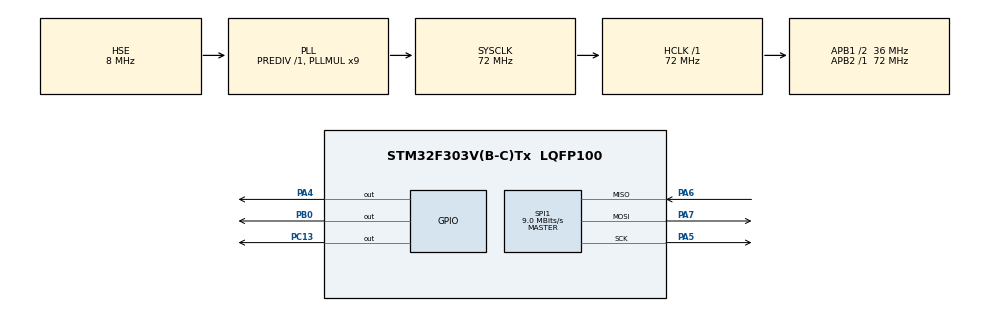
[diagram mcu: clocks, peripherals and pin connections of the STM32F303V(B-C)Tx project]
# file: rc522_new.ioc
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Mcu.Family=STM32F3
Mcu.Name=STM32F303V(B-C)Tx
Mcu.Package=LQFP100
NVIC.PriorityGroup=NVIC_PRIORITYGROUP_4
PA13.Mode=Serial_Wire
PA13.Signal=SYS_JTMS-SWDIO
PA14.Mode=Serial_Wire
PA14.Signal=SYS_JTCK-SWCLK
PA4.Signal=GPIO_Output
PA5.Mode=Full_Duplex_Master
PA5.Signal=SPI1_SCK
PA6.Mode=Full_Duplex_Master
PA6.Signal=SPI1_MISO
PA7.Mode=Full_Duplex_Master
PA7.Signal=SPI1_MOSI
PB0.Signal=GPIO_Output
PC13.Signal=GPIO_Output
PF0-OSC_IN.Mode=HSE-External-Oscillator
PF0-OSC_IN.Signal=RCC_OSC_IN
PF1-OSC_OUT.Mode=HSE-External-Oscillator
PF1-OSC_OUT.Signal=RCC_OSC_OUT
ProjectManager.HeapSize=0x200
ProjectManager.StackSize=0x400
ProjectManager.TargetToolchain=STM32CubeIDE
RCC.AHBFreq_Value=72000000
RCC.APB1CLKDivider=RCC_HCLK_DIV2
RCC.APB1Freq_Value=36000000
RCC.APB1TimFreq_Value=72000000
RCC.APB2Freq_Value=72000000
RCC.APB2TimFreq_Value=72000000
RCC.CortexFreq_Value=72000000
RCC.HCLKFreq_Value=72000000
RCC.HSE_VALUE=8000000
RCC.HSI_VALUE=8000000
RCC.LSE_VALUE=32768
RCC.PLLMUL=RCC_PLL_MUL9
RCC.PLLSourceVirtual=RCC_PLLSOURCE_HSE
RCC.SYSCLKFreq_VALUE=72000000
RCC.SYSCLKSourceVirtual=RCC_SYSCLKSOURCE_PLLCLK
RCC.USBFreq_Value=72000000
SPI1.BaudRatePrescaler=SPI_BAUDRATEPRESCALER_8
SPI1.CalculateBaudRate=9.0 MBits/s
SPI1.Direction=SPI_DIRECTION_2LINES
SPI1.Mode=SPI_MODE_MASTER
SPI1.VirtualType=VM_MASTER
board=custom

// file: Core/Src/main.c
/* USER CODE BEGIN Header */
/**
  ******************************************************************************
  * @file           : main.c
  * @brief          : Main program body
  ******************************************************************************
  * @attention
  *
  * Copyright (c) 2024 STMicroelectronics.
  * All rights reserved.
  *
  * This software is licensed under terms that can be found in the LICENSE file
  * in the root directory of this software component.
  * If no LICENSE file comes with this software, it is provided AS-IS.
  *
  ******************************************************************************
  */
/* USER CODE END Header */
#include "main.h"

/* USER CODE BEGIN Includes */
#include "rc522.h"
#include <string.h>
#include "stm32f3xx_hal.h"
/* USER CODE END Includes */

/* USER CODE BEGIN PD */
#define TIMEOUT_MS 2000  // Timeout period in milliseconds
/* USER CODE END PD */

SPI_HandleTypeDef hspi1;

/* USER CODE BEGIN PV */
uint8_t stored_uid[5] = {172, 74, 39, 204, 13};  // Pre-stored UID
uint8_t current_uid[5];  // Buffer to store the UID read from the RFID card
uint8_t sNum[5];  // Buffer to store the UID for live expression observation
uint8_t status;   // Status of MFRC522 functions
char uid_match;   // Character to indicate if UID matches
uint32_t last_detected_time = 0;  // Time when the last card was detected
/* USER CODE END PV */

void SystemClock_Config(void);
static void MX_GPIO_Init(void);
static void MX_SPI1_Init(void);

int main(void)
{

  /* MCU Configuration--------------------------------------------------------*/

  /* Reset of all peripherals, Initializes the Flash interface and the Systick. */
	HAL_Init();

  /* Configure the system clock */
  SystemClock_Config();

  /* Initialize all configured peripherals */
  MX_GPIO_Init();
  MX_SPI1_Init();
  MFRC522_Init();  // Initialize the MFRC522 module

  /* Infinite loop */
  /* USER CODE BEGIN WHILE */
  while (1)
  {
    // Check for a card presence
    status = MFRC522_Request(PICC_REQIDL, current_uid);
    if (status == MI_OK) {
      // If a card is detected, proceed to read the UID
      status = MFRC522_Anticoll(current_uid);
      if (status == MI_OK) {
        // Copy the UID to sNum for live expression observation
        memcpy(sNum, current_uid, 5);

        // Check if the UID matches the pre-stored UID
        if (memcmp(sNum, stored_uid, 5) == 0) {
          uid_match = 'Y';
          HAL_GPIO_WritePin(GPIOA, GPIO_PIN_8, GPIO_PIN_SET);

        } else {
          uid_match = 'N';
          HAL_GPIO_WritePin(GPIOA, GPIO_PIN_8, GPIO_PIN_RESET);
        }

        // Update the last detected time
        last_detected_time = HAL_GetTick();

        HAL_Delay(100);
        // Optionally, toggle an LED for visual confirmation
        HAL_GPIO_TogglePin(GPIOC, GPIO_PIN_13);
      }
    }

    // Check if the timeout period has passed
    if (HAL_GetTick() - last_detected_time > TIMEOUT_MS) {
      // Clear the sNum and set uid_match to '\0' if no card is detected
      memset(sNum, 0, sizeof(sNum));
      uid_match = '\0';
    }

    HAL_Delay(100);  // Add a small delay to prevent continuous reading
  }
  /* USER CODE END WHILE */

}

void SystemClock_Config(void)
{
  RCC_OscInitTypeDef RCC_OscInitStruct = {0};
  RCC_ClkInitTypeDef RCC_ClkInitStruct = {0};

  /** Initializes the RCC Oscillators according to the specified parameters
  * in the RCC_OscInitTypeDef structure.
  */
  RCC_OscInitStruct.OscillatorType = RCC_OSCILLATORTYPE_HSE;
  RCC_OscInitStruct.HSEState = RCC_HSE_ON;
  RCC_OscInitStruct.HSEPredivValue = RCC_HSE_PREDIV_DIV1;
  RCC_OscInitStruct.HSIState = RCC_HSI_ON;
  RCC_OscInitStruct.PLL.PLLState = RCC_PLL_ON;
  RCC_OscInitStruct.PLL.PLLSource = RCC_PLLSOURCE_HSE;
  RCC_OscInitStruct.PLL.PLLMUL = RCC_PLL_MUL9;
  if (HAL_RCC_OscConfig(&RCC_OscInitStruct) != HAL_OK)
  {
    Error_Handler();
  }

  /** Initializes the CPU, AHB and APB buses clocks
  */
  RCC_ClkInitStruct.ClockType = RCC_CLOCKTYPE_HCLK|RCC_CLOCKTYPE_SYSCLK
                              |RCC_CLOCKTYPE_PCLK1|RCC_CLOCKTYPE_PCLK2;
  RCC_ClkInitStruct.SYSCLKSource = RCC_SYSCLKSOURCE_PLLCLK;
  RCC_ClkInitStruct.AHBCLKDivider = RCC_SYSCLK_DIV1;
  RCC_ClkInitStruct.APB1CLKDivider = RCC_HCLK_DIV2;
  RCC_ClkInitStruct.APB2CLKDivider = RCC_HCLK_DIV1;

  if (HAL_RCC_ClockConfig(&RCC_ClkInitStruct, FLASH_LATENCY_2) != HAL_OK)
  {
    Error_Handler();
  }
}

static void MX_SPI1_Init(void)
{

  /* SPI1 parameter configuration*/
  hspi1.Instance = SPI1;
  hspi1.Init.Mode = SPI_MODE_MASTER;
  hspi1.Init.Direction = SPI_DIRECTION_2LINES;
  hspi1.Init.DataSize = SPI_DATASIZE_8BIT;  // Corrected data size
  hspi1.Init.CLKPolarity = SPI_POLARITY_LOW;
  hspi1.Init.CLKPhase = SPI_PHASE_1EDGE;
  hspi1.Init.NSS = SPI_NSS_SOFT;
  hspi1.Init.BaudRatePrescaler = SPI_BAUDRATEPRESCALER_8;
  hspi1.Init.FirstBit = SPI_FIRSTBIT_MSB;
  hspi1.Init.TIMode = SPI_TIMODE_DISABLE;
  hspi1.Init.CRCCalculation = SPI_CRCCALCULATION_DISABLE;
  hspi1.Init.CRCPolynomial = 7;
  if (HAL_SPI_Init(&hspi1) != HAL_OK)
  {
    Error_Handler();
  }

}

static void MX_GPIO_Init(void)
{
  GPIO_InitTypeDef GPIO_InitStruct = {0};

  /* GPIO Ports Clock Enable */
  __HAL_RCC_GPIOC_CLK_ENABLE();
  __HAL_RCC_GPIOF_CLK_ENABLE();
  __HAL_RCC_GPIOA_CLK_ENABLE();
  __HAL_RCC_GPIOB_CLK_ENABLE();

  /*Configure GPIO pin Output Level */
  HAL_GPIO_WritePin(GPIOC, GPIO_PIN_13, GPIO_PIN_RESET);

  /*Configure GPIO pin Output Level */
  HAL_GPIO_WritePin(GPIOA, GPIO_PIN_4, GPIO_PIN_RESET);

  /*Configure GPIO pin Output Level */
  HAL_GPIO_WritePin(GPIOB, GPIO_PIN_0, GPIO_PIN_RESET);

  /*Configure GPIO pin : PC13 */
  GPIO_InitStruct.Pin = GPIO_PIN_13;
  GPIO_InitStruct.Mode = GPIO_MODE_OUTPUT_PP;
  GPIO_InitStruct.Pull = GPIO_NOPULL;
  GPIO_InitStruct.Speed = GPIO_SPEED_FREQ_LOW;
  HAL_GPIO_Init(GPIOC, &GPIO_InitStruct);

  /*Configure GPIO pin: PA8 */
  GPIO_InitStruct.Pin = GPIO_PIN_8;
  GPIO_InitStruct.Mode = GPIO_MODE_OUTPUT_PP;
  GPIO_InitStruct.Pull = GPIO_NOPULL;
  GPIO_InitStruct.Speed = GPIO_SPEED_FREQ_LOW;
  HAL_GPIO_Init(GPIOA, &GPIO_InitStruct);

  /*Configure GPIO pin : PA4 */
  GPIO_InitStruct.Pin = GPIO_PIN_4;
  GPIO_InitStruct.Mode = GPIO_MODE_OUTPUT_PP;
  GPIO_InitStruct.Pull = GPIO_NOPULL;
  GPIO_InitStruct.Speed = GPIO_SPEED_FREQ_LOW;
  HAL_GPIO_Init(GPIOA, &GPIO_InitStruct);

  /*Configure GPIO pin : PB0 */
  GPIO_InitStruct.Pin = GPIO_PIN_0;
  GPIO_InitStruct.Mode = GPIO_MODE_OUTPUT_PP;
  GPIO_InitStruct.Pull = GPIO_NOPULL;
  GPIO_InitStruct.Speed = GPIO_SPEED_FREQ_LOW;
  HAL_GPIO_Init(GPIOB, &GPIO_InitStruct);

}

void Error_Handler(void)
{
  __disable_irq();
  while (1)
  {
  }
}
